# f28p65x_mindb_lut_regs register map
Vendor: Texas Instruments
Peripheral module from a debugger description file (folder C2000).
Address unit: 16 bits
Registers are 32-bit, read-write, no defined reset value unless marked. A register's access mark holds for its fields unless they carry their own. Offsets are as the file gives them; lines under a group give offsets from that group; [hi:lo] are bit positions; {n}, {i} and the like mark numbered series; 'fields as' and 'values as' point back to an identical list; <NAME> marks a mode.

## MINDB_LUT_REGS — MINDB LUT Registers
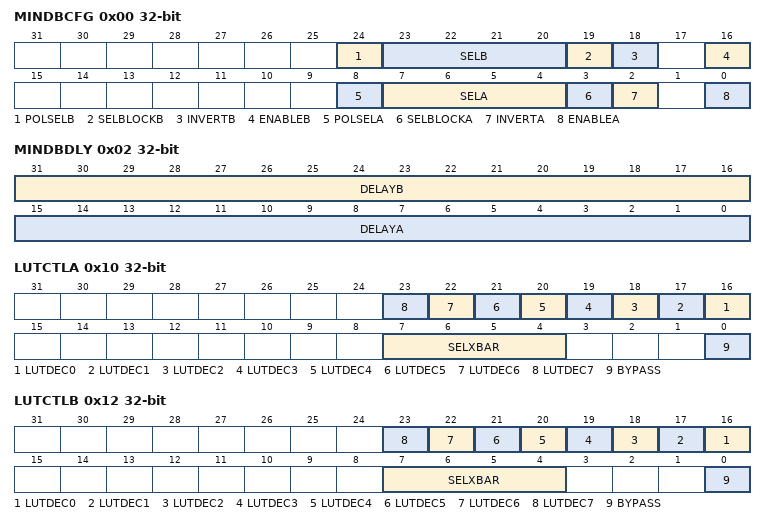
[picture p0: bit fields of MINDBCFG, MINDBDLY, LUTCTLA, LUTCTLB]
0x00 MINDBCFG — Minimum dead band configuration register.
  [24] POLSELB — Select signal for the AND OR logic of PWMB
  [23:20] SELB — Reference source select on PWMB min dead band logic.
  [19] SELBLOCKB — BLOCK signal source select on PWMB
  [18] INVERTB — Invert the selected reference signal on PWMB
  [16] ENABLEB — Minimum dead band logic enable on PWMB
  [8] POLSELA — Select signal for the AND OR logic of PWMA
  [7:4] SELA — Reference source select on PWMA min dead band logic.
  [3] SELBLOCKA — BLOCK signal source select on PWMA
  [2] INVERTA — Invert the selected reference signal on PWMA
  [0] ENABLEA — Minimum dead band logic enable on PWMA
0x02 MINDBDLY — Minimum dead band delay register
  [31:16] DELAYB — Minimum dead band delay on PWMB
  [15:0] DELAYA — Minimum dead band delay on PWMA
0x10 LUTCTLA — LUT control register on PWMA
  [n+16] LUTDEC{n} (n=0..7) — LUT output PWMA value on decoding {n}
  [7:4] SELXBAR — ICSS XBAR select
  [0] BYPASS — Bypass LUTA
0x12 LUTCTLB — LUT control register on PWMB
  [n+16] LUTDEC{n} (n=0..7) — LUT output PWMB value on decoding {n}
  [7:4] SELXBAR — ICSS XBAR select
  [0] BYPASS — Bypass LUTB
